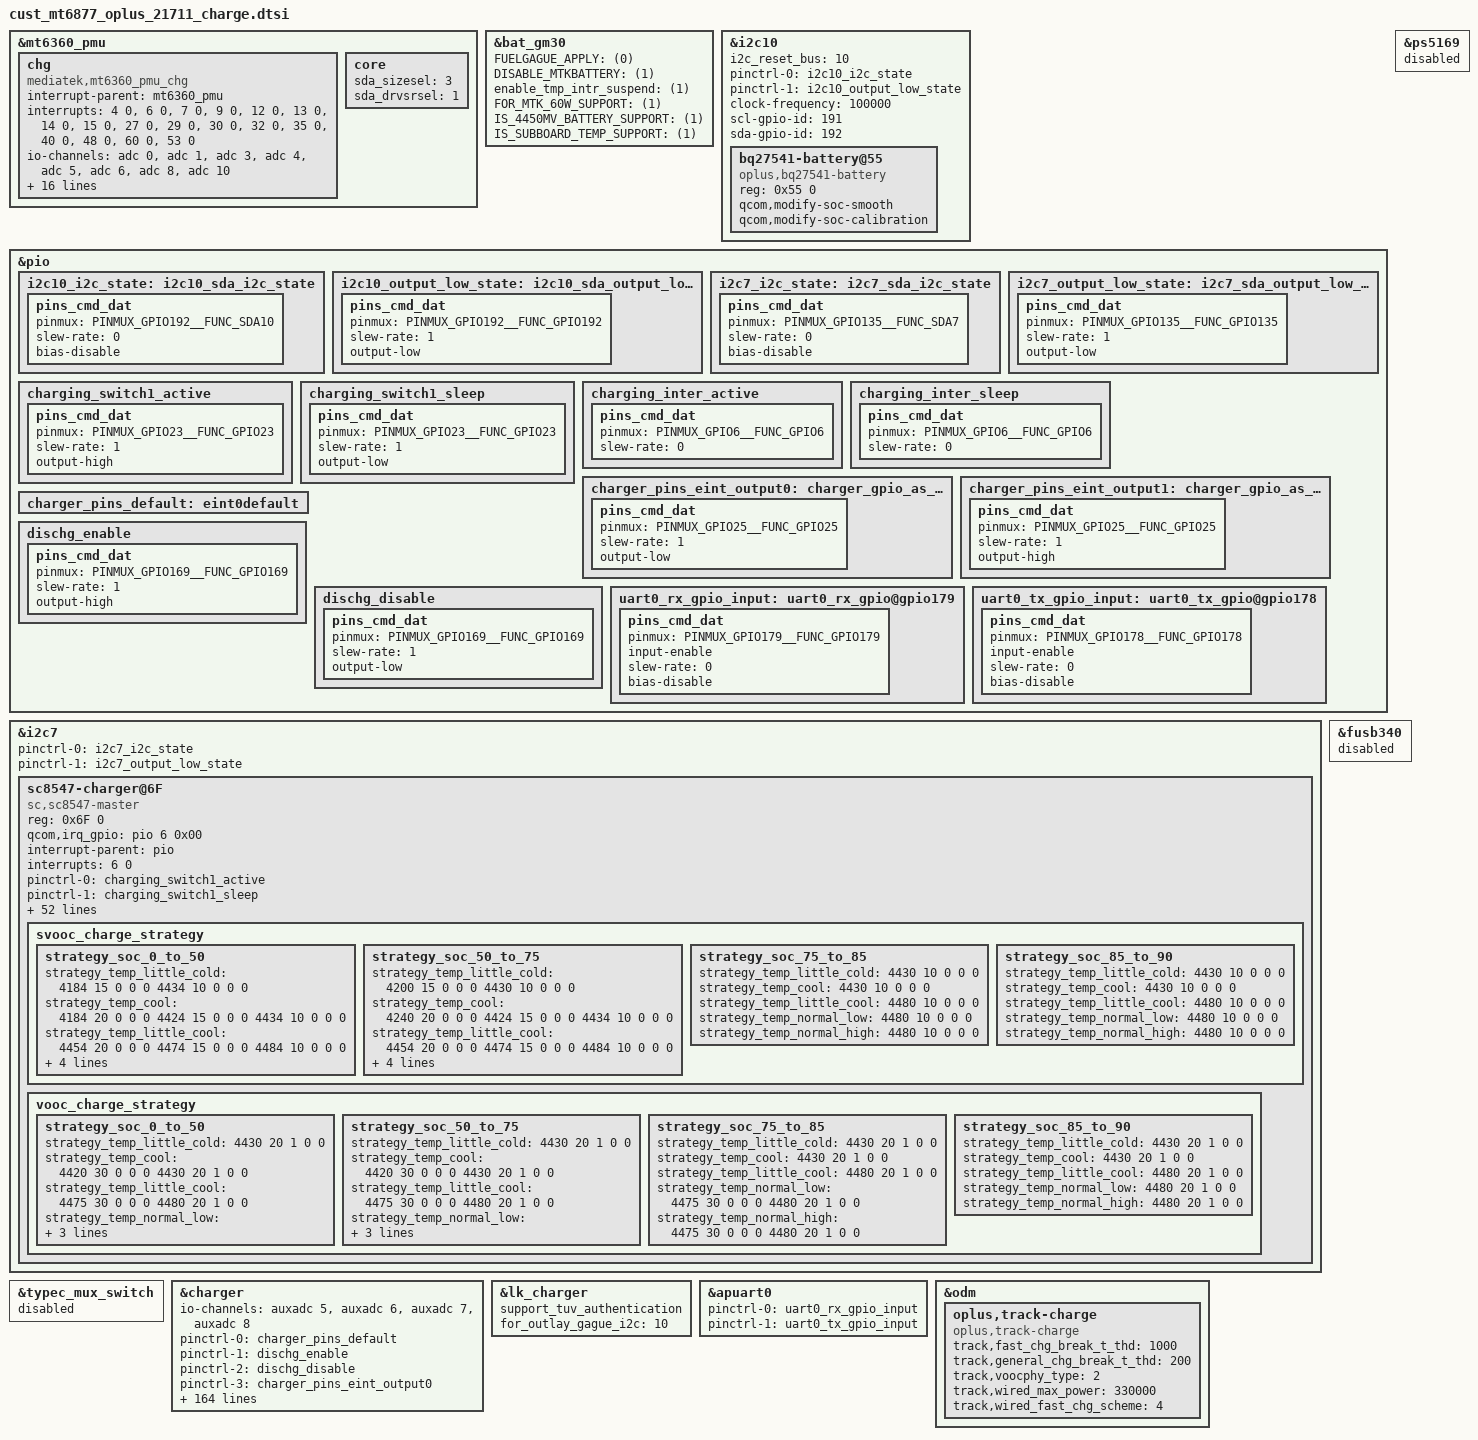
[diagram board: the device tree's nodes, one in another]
&mt6360_pmu {
	chg {
		compatible = "mediatek,mt6360_pmu_chg";
		interrupt-parent = <&mt6360_pmu>;
		interrupts = <4 0>, <6 0>, <7 0>, <9 0>,
				<12 0>, <13 0>, <14 0>, <15 0>,
				<27 0>, <29 0>, <30 0>, <32 0>,
				<35 0>, <40 0>, <48 0>, <60 0>,
				<53 0>;
		interrupt-names = "chg_treg_evt", "chg_mivr_evt",
				"pwr_rdy_evt", "chg_batsysuv_evt",
				"chg_vsysuv_evt", "chg_vsysov_evt",
				"chg_vbatov_evt", "chg_vbusov_evt",
				"chg_tmri", "chg_adpbadi",
				"chg_rvpi",  "chg_aiccmeasl",
				"wdtmri", "pumpx_donei",
				"attachi", "chrdet_ext_evt",
				"hvdcp_det";
		io-channels = <&adc 0>, <&adc 1>, <&adc 3>, <&adc 4>,
				<&adc 5>, <&adc 6>, <&adc 8>, <&adc 10>;
		io-channel-names = "USBID", "VBUSDIV5", "VSYS", "VBAT",
				"IBUS", "IBAT", "TEMP_JC", "TS";
		chg_name = "primary_chg";
		ichg = <2000000>;               /* uA */
		aicr = <500000>;                /* uA */
		mivr = <4400000>;               /* uV */
		cv = <4350000>;                 /* uA */
		ieoc = <150000>;                /* uA */
		safety_timer = <12>;            /* hour */
		ircmp_resistor = <25000>;       /* uohm */
		ircmp_vclamp = <32000>;         /* uV */
		en_te = <1>;
		en_wdt = <1>;
		aicc_once = <1>;
		post_aicc = <1>;
		batoc_notify = <0>;
	};
};

&bat_gm30 {
	FUELGAGUE_APPLY = <(0)>;
	DISABLE_MTKBATTERY = <(1)>;
	enable_tmp_intr_suspend = <(1)>;

	FOR_MTK_60W_SUPPORT = <(1)>;
	IS_4450MV_BATTERY_SUPPORT = <(1)>;
	IS_SUBBOARD_TEMP_SUPPORT = <(1)>;

};

&i2c10 {
	i2c_reset_bus = <10>;
	pinctrl-names = "i2c-state", "output-low-state";
	pinctrl-0 = <&i2c10_i2c_state>;
	pinctrl-1 = <&i2c10_output_low_state>;
};
&pio {
	i2c10_i2c_state: i2c10_sda_i2c_state {
		pins_cmd_dat {
			pinmux = <PINMUX_GPIO192__FUNC_SDA10>;
			slew-rate = <0>;
			bias-disable;
		};
	};
	i2c10_output_low_state: i2c10_sda_output_low_state {
		pins_cmd_dat {
			pinmux = <PINMUX_GPIO192__FUNC_GPIO192>;
			slew-rate = <1>;
			output-low;
		};
	};
};

&i2c10 {
	status = "okay";
	clock-frequency = <100000>;
	scl-gpio-id = <191>;
 	sda-gpio-id = <192>;
	bq27541-battery@55 {
		status = "okay";
		compatible = "oplus,bq27541-battery";
		reg = <0x55 0>;
		qcom,modify-soc-smooth;
		qcom,modify-soc-calibration;
	};
};

&mt6360_pmu {
	core {
		sda_sizesel = <3>;
		sda_drvsrsel = <1>;
	};
	chg {
		support_hvdcp;
		cdp_first_ignore;
	};
};

&i2c7 {
	pinctrl-names = "i2c-state", "output-low-state";
	pinctrl-0 = <&i2c7_i2c_state>;
	pinctrl-1 = <&i2c7_output_low_state>;
};
&pio {
	i2c7_i2c_state: i2c7_sda_i2c_state {
		pins_cmd_dat {
			pinmux = <PINMUX_GPIO135__FUNC_SDA7>;
			slew-rate = <0>;
			bias-disable;
		};
	};
	i2c7_output_low_state: i2c7_sda_output_low_state {
		pins_cmd_dat {
			pinmux = <PINMUX_GPIO135__FUNC_GPIO135>;
			slew-rate = <1>;
			output-low;
		};
	};
};



&i2c7 {
	sc8547-charger@6F{
		status = "okay";
		compatible = "sc,sc8547-master";
		reg = <0x6F 0>;

		qcom,irq_gpio = <&pio 6 0x00>;
		interrupt-parent = <&pio>;
		interrupts = <6 0>;

		pinctrl-names = "switch1_act_switch2_act", "switch1_sleep_switch2_sleep",
					"charging_inter_active", "charging_inter_sleep";
		pinctrl-0 = <&charging_switch1_active>;
		pinctrl-1 = <&charging_switch1_sleep>;
		pinctrl-2 = <&charging_inter_active>;
		pinctrl-3 = <&charging_inter_sleep>;

		qcom,charging_switch1-gpio = <&pio 23 0x00>;

		qcom,external_gauge_support;

		qcom,voocphy_current_default = <30>;
		qcom,copycat_vooc_support;

		qcom,svooc_cool_down_current_limit = <120 20 20 20 30 40 50 60 70 80 90 100>;
		qcom,vooc_cool_down_current_limit = <60 20 20 20 30 40 50 60>;

		qcom,vooc_multistep_initial_batt_temp = <1000>;
		qcom,vooc_little_cool_temp = <160>;
		qcom,vooc_cool_temp = <120>;
		qcom,vooc_little_cold_temp = <50>;
		qcom,vooc_normal_low_temp = <250>;
		qcom,vooc_strategy_normal_current = <120>;
		qcom,vooc_normal_to_little_cool_current = <100>;
		qcom,vooc_batt_over_high_temp = <440>;
		qcom,vooc_batt_over_low_temp = <0>;

		qcom,vooc_strategy1_batt_high_temp0 = <395>;
		qcom,vooc_strategy1_batt_high_temp1 = <420>;
		qcom,vooc_strategy1_batt_high_temp2 = <440>;
		qcom,vooc_strategy1_batt_low_temp2 = <430>;
		qcom,vooc_strategy1_batt_low_temp1 = <410>;
		qcom,vooc_strategy1_batt_low_temp0 = <390>;

		qcom,vooc_strategy1_high_current0 = <40>;
		qcom,vooc_strategy1_high_current1 = <30>;
		qcom,vooc_strategy1_high_current2 = <20>;
		qcom,vooc_strategy1_low_current2 = <30>;
		qcom,vooc_strategy1_low_current1 = <40>;
		qcom,vooc_strategy1_low_current0 = <50>;

		qcom,voocphy_freq_mincore = <980000>;
		qcom,voocphy_freq_midcore = <1335000>;
		qcom,voocphy_freq_maxcore = <1350000>;
		qcom,voocphy_current_change_timeout = <100>;

		qcom,voocphy_ibat_over_current = <13500>;
		qcom,voocphy_cp_max_ibus = <3500>;

		qcom,vooc_little_cold_full_voltage = <4430>;
		qcom,vooc_cool_full_voltage = <4430>;
		qcom,vooc_1time_full_voltage = <4484>;
		qcom,vooc_ntime_full_voltage = <4484>;
		qcom,low_curr_full_t1 = <120>;
		qcom,low_curr_full_t2 = <350>;
		qcom,low_curr_full_t3 = <430>;
		qcom,range1_low_curr_full = <1100 4470
						1000 4460
						900 4450>;
		qcom,range2_low_curr_full = <1200 4470
						1100 4460
						1000 4450>;
		svooc_batt_sys_curve = <0 0 1 1 1 1 0	// 3000mA
					0 0 0 0 0 0 1	// 3414mV
					0 0 1 0 1 0 0	// 2000mA
					1 1 1 0 0 1 0	// 4550mV
					0 0 0 1 0 1 0	// 1000mA
					1 1 1 0 0 1 0>;	// 4550mV

		vooc_batt_sys_curve =  <0 0 1 1 1 1 0	// 3000mA
					0 0 0 0 0 0 1	// 3414mV
					0 0 1 0 1 0 0	// 2000mA
					1 1 1 0 0 1 0	// 4550mV
					0 0 0 1 0 1 0	// 1000mA
					1 1 1 0 0 1 0>;	// 4550mV

		svooc_charge_strategy {
			strategy_soc_0_to_50 {
				strategy_temp_little_cold =	<4184 15 0 0 0
								 4434 10 0 0 0>;
				strategy_temp_cool =		<4184 20 0 0 0
								 4424 15 0 0 0
								 4434 10 0 0 0>;
				strategy_temp_little_cool = 	<4454 20 0 0 0
								 4474 15 0 0 0
								 4484 10 0 0 0>;
				strategy_temp_normal_low =	<4200 30 0 600 0
								 4454 25 0 600 0
								 4454 20 0 0 0
								 4474 18 0 0 0
								 4474 15 0 0 0
								 4484 10 0 0 0>;
				strategy_temp_normal_high =	<4200 30 0 600 0
								 4454 25 0 600 0
								 4454 20 0 0 0
								 4474 18 0 0 0
								 4474 15 0 0 0
								 4485 10 0 0 0>;
			};

			strategy_soc_50_to_75 {
				strategy_temp_little_cold =	<4200 15 0 0 0
								 4430 10 0 0 0>;
				strategy_temp_cool =		<4240 20 0 0 0
								 4424 15 0 0 0
								 4434 10 0 0 0>;
				strategy_temp_little_cool =	<4454 20 0 0 0
								 4474 15 0 0 0
								 4484 10 0 0 0>;
				strategy_temp_normal_low =	<4200 30 0 600 0
								 4454 25 0 600 0
								 4454 20 0 0 0
								 4474 18 0 0 0
								 4474 15 0 0 0
								 4484 10 0 0 0>;
				strategy_temp_normal_high =	<4200 30 0 600 0
								 4454 25 0 600 0
								 4454 20 0 0 0
								 4474 18 0 0 0
								 4474 15 0 0 0
								 4484 10 0 0 0>;
			};

			strategy_soc_75_to_85 {
				strategy_temp_little_cold = 	<4430 10 0 0 0>;
				strategy_temp_cool =		<4430 10 0 0 0>;
				strategy_temp_little_cool =	<4480 10 0 0 0>;
				strategy_temp_normal_low =	<4480 10 0 0 0>;
				strategy_temp_normal_high =	<4480 10 0 0 0>;
			};

			strategy_soc_85_to_90 {
				strategy_temp_little_cold = 	<4430 10 0 0 0>;
				strategy_temp_cool =		<4430 10 0 0 0>;
				strategy_temp_little_cool =	<4480 10 0 0 0>;
				strategy_temp_normal_low =	<4480 10 0 0 0>;
				strategy_temp_normal_high =	<4480 10 0 0 0>;
			};
		};

		vooc_charge_strategy {
			strategy_soc_0_to_50 {
				strategy_temp_little_cold = 	<4430 20 1 0 0>;
				strategy_temp_cool =		<4420 30 0 0 0
								 4430 20 1 0 0>;
				strategy_temp_little_cool =	<4475 30 0 0 0
								 4480 20 1 0 0>;
				strategy_temp_normal_low =	<4475 30 0 0 0
								 4480 20 1 0 0>;
				strategy_temp_normal_high =	<4475 30 0 0 0
								 4480 20 1 0 0>;
			};

			strategy_soc_50_to_75 {
				strategy_temp_little_cold =	<4430 20 1 0 0>;
				strategy_temp_cool =		<4420 30 0 0 0
								 4430 20 1 0 0>;
				strategy_temp_little_cool =	<4475 30 0 0 0
								 4480 20 1 0 0>;
				strategy_temp_normal_low =	<4475 30 0 0 0
								 4480 20 1 0 0>;
				strategy_temp_normal_high =	<4475 30 0 0 0
								 4480 20 1 0 0>;
			};

			strategy_soc_75_to_85 {
				strategy_temp_little_cold =	<4430 20 1 0 0>;
				strategy_temp_cool =		<4430 20 1 0 0>;
				strategy_temp_little_cool =	<4480 20 1 0 0>;
				strategy_temp_normal_low =	<4475 30 0 0 0
								 4480 20 1 0 0>;
				strategy_temp_normal_high =	<4475 30 0 0 0
								 4480 20 1 0 0>;
			};

			strategy_soc_85_to_90 {
				strategy_temp_little_cold =	<4430 20 1 0 0>;
				strategy_temp_cool =		<4430 20 1 0 0>;
				strategy_temp_little_cool =	<4480 20 1 0 0>;
				strategy_temp_normal_low =	<4480 20 1 0 0>;
				strategy_temp_normal_high =	<4480 20 1 0 0>;
			};
		};

	};
};

&typec_mux_switch {
	status = "disabled";
};

&ps5169{
	status = "disabled";
};

&fusb340 {
	status = "disabled";
};

&pio {
	charging_switch1_active: charging_switch1_active {
		pins_cmd_dat {
			pinmux = <PINMUX_GPIO23__FUNC_GPIO23>;
			slew-rate = <1>;
			output-high;
		};
	};
	charging_switch1_sleep: charging_switch1_sleep {
		pins_cmd_dat {
			pinmux = <PINMUX_GPIO23__FUNC_GPIO23>;
			slew-rate = <1>;
			output-low;
		};
	};

	charging_inter_active: charging_inter_active {
		pins_cmd_dat {
			pinmux = <PINMUX_GPIO6__FUNC_GPIO6>;
			slew-rate = <0>;
        };
    };
	charging_inter_sleep: charging_inter_sleep {
		pins_cmd_dat {
            pinmux = <PINMUX_GPIO6__FUNC_GPIO6>;
            slew-rate = <0>;
        };
    };

	charger_pins_eint_output0: charger_gpio_as_output_low {
		pins_cmd_dat {
			pinmux = <PINMUX_GPIO25__FUNC_GPIO25>;
			slew-rate = <1>;
			output-low;
		};
	};

	charger_pins_eint_output1: charger_gpio_as_output_high {
		pins_cmd_dat {
			pinmux = <PINMUX_GPIO25__FUNC_GPIO25>;
			slew-rate = <1>;
			output-high;
		};
	};
};

&charger {
	io-channels =  <&auxadc 5>,<&auxadc 6>,<&auxadc 7>,
		<&auxadc 8>;
	io-channel-names = "auxadc6-subboard_temp","auxadc3-chargeric_temp","auxadc4-usb_temp_v_l",
		"auxadc5-usb_temp_v_r";

	pinctrl-names = "default",
				"dischg_enable",
				"dischg_disable",
				"charger_gpio_as_output_low",
				"charger_gpio_as_output_high";
	pinctrl-0 = <&charger_pins_default>;
	pinctrl-1 = <&dischg_enable>;
	pinctrl-2 = <&dischg_disable>;
	pinctrl-3 = <&charger_pins_eint_output0>;
	pinctrl-4 = <&charger_pins_eint_output1>;


	qcom,pd_input_current_charger_ma = <2000>;
	qcom,qc_input_current_charger_ma = <2000>;
	qcom,input_current_charger_ma = <2000>;
	qcom,input_current_usb_ma = <500>;
	qcom,input_current_cdp_ma = <1500>;
	qcom,input_current_camera_ma = <1200>;
	qcom,input_current_calling_ma = <1500>;

	qcom,led_warm_bat_decidegc = <350>;
	qcom,led_high_bat_decidegc = <370>;
	qcom,input_current_led_ma = <1200>;
	qcom,input_current_led_ma_high = <1200>;
	qcom,input_current_led_ma_warm = <1500>;
	qcom,input_current_led_ma_normal = <2300>;
	qcom,input_current_led_ma_forcmcc = <500>;
	qcom,input_current_led_ma_limit_high = <1200>;

	qcom,vooc_temp_bat_normal_decidegc = <350>;
	qcom,vooc_temp_bat_warm_decidegc = <370>;
	qcom,vooc_temp_bat_hot_decidegc = <440>;
	qcom,input_current_vooc_led_ma_high = <1200>;
	qcom,input_current_vooc_led_ma_warm = <1800>;
	qcom,input_current_vooc_led_ma_normal = <3600>;
	qcom,input_current_vooc_ma_normal = <3600>;
	qcom,input_current_vooc_ma_warm = <3200>;
	qcom,input_current_vooc_ma_high = <2200>;

	qcom,overtemp_bat_decidegc = <350>;
	qcom,iterm_disabled = <0>;

	qcom,iterm_ma = <260>;
	qcom,recharge-mv = <100>;

	qcom,batt_capacity_mah = <5000>; /*typical capacity*/

	qcom,usb_high_than_bat_decidegc = <168>;

	qcom,removed_bat_decidegc = <150>;  /* < -15C */

	qcom,cold_bat_decidegc = <20>;  /* -2C ~ 0C */
	qcom,temp_cold_vfloat_mv = <3980>;
	qcom,temp_cold_fastchg_current_ma = <400>;

	qcom,little_cold_bat_decidegc = <0>;    /* 0C ~ 5C */
	qcom,temp_little_cold_vfloat_mv = <4435>;
	qcom,temp_little_cold_fastchg_current_ma_high = <2200>;
	qcom,temp_little_cold_fastchg_current_ma_low = <2200>;
	qcom,temp_little_cold_fastchg_current_ma = <1076>;
	qcom,qc_temp_little_cold_fastchg_current_ma_high = <2594>;
	qcom,qc_temp_little_cold_fastchg_current_ma_low = <3300>;
	qcom,pd_temp_little_cold_fastchg_current_ma_high = <2594>;
	qcom,pd_temp_little_cold_fastchg_current_ma_low = <3300>;

	qcom,cool_bat_decidegc = <50>;  /* 5C ~ 12C */
	qcom,temp_cool_vfloat_mv = <4435>;
	qcom,temp_cool_fastchg_current_ma_high = <2200>;
	qcom,temp_cool_fastchg_current_ma_low = <2200>;
	qcom,qc_temp_cool_fastchg_current_ma_high = <3300>;
	qcom,qc_temp_cool_fastchg_current_ma_low = <3300>;
	qcom,pd_temp_cool_fastchg_current_ma_high = <3300>;
	qcom,pd_temp_cool_fastchg_current_ma_low = <3300>;

	qcom,little_cool_bat_decidegc = <120>;  /* 12C ~ 16C */
	qcom,temp_little_cool_vfloat_mv = <4435>;
	qcom,temp_little_cool_fastchg_current_ma = <2200>;
	qcom,pd_temp_little_cool_fastchg_current_ma = <3300>;
	qcom,qc_temp_little_cool_fastchg_current_ma = <3300>;

	qcom,normal_bat_decidegc = <160>;       /* 16C ~ 45C */
	qcom,temp_normal_vfloat_mv = <4435>;
	qcom,temp_normal_fastchg_current_ma = <2200>;
	qcom,pd_temp_normal_fastchg_current_ma = <3300>;
	qcom,qc_temp_normal_fastchg_current_ma = <3300>;

	qcom,warm_bat_decidegc = <450>;         /* 45C ~ 53C */ /*8pin Bat Vooc project need add 3 degree C*/
	qcom,temp_warm_vfloat_mv = <4130>;
	qcom,temp_warm_fastchg_current_ma = <1350>;
	qcom,pd_temp_warm_fastchg_current_ma = <1350>;
	qcom,qc_temp_warm_fastchg_current_ma = <1350>;
	qcom,temp_warm_fastchg_current_ma_led_on = <500>;

	qcom,hot_bat_decidegc = <530>;  /* > 53C */

	qcom,non_standard_vfloat_mv = <3980>;
	qcom,non_standard_fastchg_current_ma = <512>;

	qcom,short_c_bat_cv_mv = <4330>;
	qcom,short_c_bat_vfloat_mv = <3800>;
	qcom,short_c_bat_fastchg_current_ma = <512>;
	qcom,short_c_bat_vfloat_sw_limit = <3750>;

	qcom,cold_vfloat_sw_limit = <3930>;
	qcom,little_cold_vfloat_sw_limit = <4385>;
	qcom,cool_vfloat_sw_limit = <4385>;
	qcom,little_cool_vfloat_sw_limit = <4385>;
	qcom,normal_vfloat_sw_limit = <4385>;
	qcom,warm_vfloat_sw_limit = <4080>;
	qcom,non_standard_vfloat_sw_limit = <3930>;

	qcom,max_chg_time_sec = <70272>;
	qcom,charger_hv_thr = <10000>;
	qcom,charger_recv_thr = <9800>;
	qcom,charger_lv_thr = <3400>;
	qcom,vbatt_full_thr = <4400>;
	qcom,vbatt_hv_thr = <4550>;

	qcom,vfloat_step_mv = <8>;
	qcom,non_standard_vfloat_over_sw_limit = <3980>;
	qcom,cold_vfloat_over_sw_limit = <3980>;
	qcom,little_cold_vfloat_over_sw_limit = <4440>;
	qcom,cool_vfloat_over_sw_limit = <4440>;
	qcom,little_cool_vfloat_over_sw_limit = <4440>;
	qcom,normal_vfloat_over_sw_limit = <4440>;
	qcom,warm_vfloat_over_sw_limit = <4130>;

	qcom,vbatt_power_off = <3300>;
	qcom,vbatt_soc_1 = <3410>;
	qcom,vooc_project = <4>;
	qcom,vbatt_num = <1>;
	qcom,new_ui_warning_support;
	qcom,smart_charging_screenoff;
	qcom,smart_charge_version = <1>;

	qcom,normal_vterm_hw_inc = <18>;
	qcom,non_normal_vterm_hw_inc = <18>;
	qcom,usbtemp_batttemp_gap = <12>;

	qcom,ff1_normal_fastchg_ma = <1500>;
	qcom,ff1_warm_fastchg_ma = <1500>;	/* 35C ~ 40c */
	qcom,ff1_exit_step_ma = <300>;
	qcom,ff1_warm_exit_step_ma = <100>;
	qcom,ffc2_normal_fastchg_ma = <1200>;/*12C~35c*/
	qcom,ffc2_warm_fastchg_ma = <1300>;	/* 35C ~ 40c */
	qcom,ffc2_temp_warm_decidegc = <350>;
	qcom,ffc2_temp_high_decidegc = <400>;
	qcom,ffc2_temp_low_decidegc = <120>;
	qcom,ffc2_exit_step_ma = <300>;
	qcom,ffc2_warm_exit_step_ma = <200>;

	qcom,ffc_normal_vfloat_sw_limit = <4480>;
	qcom,ffc2_normal_vfloat_sw_limit = <4480>;
	qcom,ffc_temp_normal_vfloat_mv = <4550>;
	qcom,ffc_normal_vfloat_over_sw_limit = <4550>;

	qcom,default_iterm_ma = <260>;
	qcom,default_temp_normal_fastchg_current_ma = <2200>;
	qcom,default_normal_vfloat_sw_limit = <4385>;
	qcom,default_temp_normal_vfloat_mv = <4435>;
	qcom,default_normal_vfloat_over_sw_limit = <4440>;
	qcom,default_temp_little_cool_fastchg_current_ma = <2200>;
	qcom,default_little_cool_vfloat_sw_limit = <4385>;
	qcom,default_temp_little_cool_vfloat_mv = <4435>;
	qcom,default_little_cool_vfloat_over_sw_limit = <4445>;

	//for PD9V or QC9V
	qcom,vbatt_pdqc_to_5v_thr = <4500>;
	qcom,vbatt_pdqc_to_9v_thr = <4500>;

	qcom,check_batt_full_by_sw;
	qcom,chg_ctrl_by_lcd;
	qcom,chg_ctrl_by_camera;
	qcom,chg_ctrl_by_calling;
	qcom,sw_vfloat_over_protect_enable;
	qcom,ffc_support;
	qcom,chargerid_vol_disable;
	qcom,support_ntc_01c_precision;
	qcom,voocphy_support = <(2)>; // AP_SINGLE_CP_VOOCPHY
	voocphy_support_display_vooc;

	qcom,external_gauge;
	qcom,chargerid_support;
	qcom,vooc_show_ui_soc_decimal;
	qcom,ui_soc_decimal_speedmin = <20>;//2A

	//GPIO config
	qcom,chargerid_switch-gpio = <&pio 25 0x00>;
	qcom,dischg-gpio = <&pio 169 0x00>;
   //USB temperature
	qcom,g_rap_pull_up_r0 = <390000>;

	qcom,vooc-max-input-volt-support = <10000>;     //10V
	qcom,vooc-max-input-current-support = <3000>;   //3A
};

&lk_charger{
	support_tuv_authentication;
	for_outlay_gague_i2c = <10>;
};

&pio {
	charger_pins_default: eint0default {
	};

	dischg_enable: dischg_enable {
		pins_cmd_dat {
			pinmux = <PINMUX_GPIO169__FUNC_GPIO169>;
			slew-rate = <1>;//0:input direction 1:output direction
			output-high;
		};
	};

	dischg_disable: dischg_disable {
		pins_cmd_dat {
			pinmux = <PINMUX_GPIO169__FUNC_GPIO169>;
			slew-rate = <1>;
			output-low;
		};
	};
};


&apuart0 {
	pinctrl-names = "uart0_rx_gpio",
			"uart0_tx_gpio";
	pinctrl-0 = <&uart0_rx_gpio_input>;
	pinctrl-1 = <&uart0_tx_gpio_input>;
	status = "okay";
};

&odm {
	oplus,track-charge {
		compatible = "oplus,track-charge";
		track,fast_chg_break_t_thd = <1000>;
		track,general_chg_break_t_thd = <200>;
		track,voocphy_type = <2>;
		track,wired_max_power = <330000>;
		track,wired_fast_chg_scheme = <4>;
	};
};

&pio {
	uart0_rx_gpio_input:uart0_rx_gpio@gpio179 {
		pins_cmd_dat {
			pinmux = <PINMUX_GPIO179__FUNC_GPIO179>;
			input-enable;
			slew-rate = <0>;
			bias-disable;
		};
	};
	uart0_tx_gpio_input:uart0_tx_gpio@gpio178 {
		pins_cmd_dat {
			pinmux = <PINMUX_GPIO178__FUNC_GPIO178>;
			input-enable;
			slew-rate = <0>;
			bias-disable;
		};
	};
};
